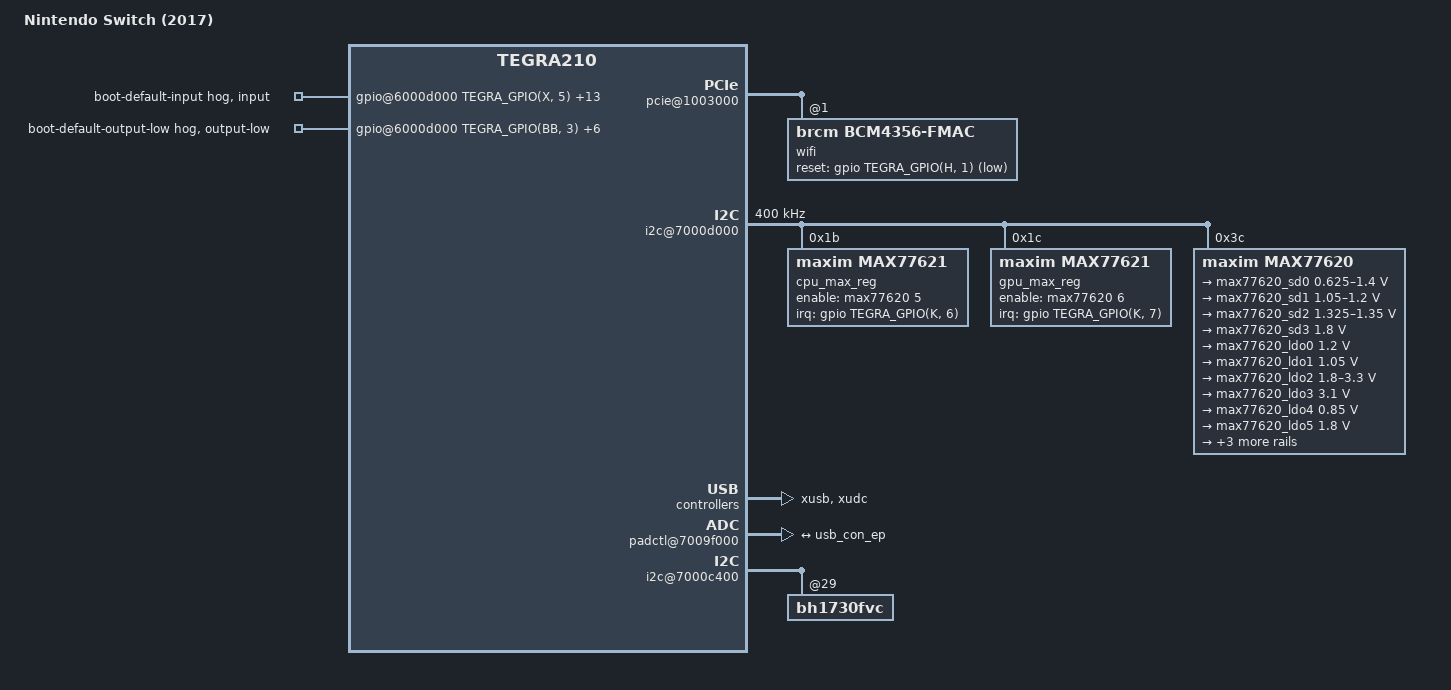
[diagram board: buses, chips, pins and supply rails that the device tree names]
// SPDX-License-Identifier: GPL-2.0
/dts-v1/;

#include "tegra210-nx.dtsi"

/ {
	model = "Nintendo Switch (2017)";
	compatible = "nintendo,icosa", "nvidia,tegra210";
	serial-number = "1234";

	#address-cells = <2>;
	#size-cells = <2>;

	external-memory-controller@7001b000 {
		status = "okay";

		clocks = <&tegra_car TEGRA210_CLK_EMC>,
			<&tegra_car TEGRA210_CLK_PLL_M>,
			<&tegra_car TEGRA210_CLK_PLL_C>,
			<&tegra_car TEGRA210_CLK_PLL_P>,
			<&tegra_car TEGRA210_CLK_CLK_M>,
			<&tegra_car TEGRA210_CLK_PLL_MB>,
			<&tegra_car TEGRA210_CLK_PLL_MB_UD>,
			<&tegra_car TEGRA210_CLK_PLL_P_UD>;

		clock-names = "emc", "pll_m", "pll_c", "pll_p", "mclk",
			"pll_mb", "pll_mb_ud", "pll_p_ud";
		#thermal-sensor-cells = <0>;

		nvidia,use-smc-emc-tables;
	};

	pcie@1003000 {
		status = "okay";

		hvddio-pex-supply = <&max77620_sd3>;
		dvddio-pex-supply = <&max77620_ldo1>;
		vddio-pex-ctl-supply = <&max77620_sd3>;

		pci@1,0 {
			phys = <&{/padctl@7009f000/pads/pcie/lanes/pcie-1}>,
				<&{/padctl@7009f000/pads/pcie/lanes/pcie-2}>,
				<&{/padctl@7009f000/pads/pcie/lanes/pcie-3}>,
				<&{/padctl@7009f000/pads/pcie/lanes/pcie-4}>;
			phy-names = "pcie-0", "pcie-1", "pcie-2", "pcie-3";
			nvidia,num-lanes = <4>;
			status = "okay";
		};

		pci@2,0 {
			phys = <&{/padctl@7009f000/pads/pcie/lanes/pcie-0}>;
			phy-names = "pcie-0";
			status = "okay";

			wifi@1 { /* PCIE-0 (Port 1) */
				status = "okay";
				compatible = "brcm,bcm4356-fmac";
				reg = <1>;
				reset-gpios = <&gpio TEGRA_GPIO(H, 1) GPIO_ACTIVE_LOW>;
			};
		};
	};

	host1x@50000000 {
		dsia: dsi@54300000 {
			avdd-dsi-csi-supply = <&max77620_gpio7>;
		};

		dc@54200000 {
			avdd_dsi_csi-supply = <&max77620_gpio7>;
		};

		sor1: sor@54580000 {
			/* use odin hdmi defaults */
			compatible = "nvidia,tegra210-sor1-odin";
		};

		vi: i2c@546c0000 {
			avdd_dsi_csi-supply = <&max77620_gpio7>;
        };
	};

	gpio@6000d000 {
		boot-default-input {
			gpio-hog;
			input;
			gpios = <
				TEGRA_GPIO(X, 5) GPIO_ACTIVE_HIGH /* Power Button (Not connected) */
				TEGRA_GPIO(Y, 1) GPIO_ACTIVE_LOW /* Home Button (RCM) */
				TEGRA_GPIO(S, 1) GPIO_ACTIVE_LOW /* Charger IC (BQ24193) Battery Charge Status */
				TEGRA_GPIO(S, 3) GPIO_ACTIVE_LOW /* Gamecard Detect */
				TEGRA_GPIO(Z, 3) GPIO_ACTIVE_LOW /* SD Card Write Protected */
				TEGRA_GPIO(H, 2) GPIO_ACTIVE_LOW /* Wi-Fi Wake Host */
				TEGRA_GPIO(H, 5) GPIO_ACTIVE_LOW /* Bluetooth - BT Module -> Wake AP */
				TEGRA_GPIO(K, 0) GPIO_ACTIVE_HIGH /* Bluetooth Gpio2 */
				TEGRA_GPIO(K, 1) GPIO_ACTIVE_HIGH /* Bluetooth Gpio3 */
				TEGRA_GPIO(K, 2) GPIO_ACTIVE_HIGH /* Bluetooth Gpio4 */
				TEGRA_GPIO(V, 3) GPIO_ACTIVE_LOW /* Unused */

				TEGRA_GPIO(P, 0) GPIO_ACTIVE_LOW  /* SDEV Odin/Modin */
				TEGRA_GPIO(BB, 2) GPIO_ACTIVE_HIGH /* Ram Code 3 */
				TEGRA_GPIO(CC, 2) GPIO_ACTIVE_HIGH /* Ram Code 2 */
			>;
			line-name = "boot-default-input";
		};

		boot-default-output-low {
			gpio-hog;
			output-low;
			gpios = <
				TEGRA_GPIO(BB, 3) GPIO_ACTIVE_HIGH /* Gamecard Reset */
				TEGRA_GPIO(V, 5) GPIO_ACTIVE_HIGH  /* USB-PD (BM92T36) Reset. Use it to reset bm92t (128 ms debounce)? */
				TEGRA_GPIO(K, 5) GPIO_ACTIVE_HIGH  /* USB-PD (BM92T36) VCONN Power Enable. HOS sets it to 0 */
				TEGRA_GPIO(J, 5) GPIO_ACTIVE_HIGH  /* Charger IC (BQ24193) Charge Select 1 */
				TEGRA_GPIO(L, 0) GPIO_ACTIVE_HIGH  /* Charger IC (BQ24193) Charge Select 2 */
				TEGRA_GPIO(H, 0) GPIO_ACTIVE_HIGH  /* Wi-Fi RF Disable */
				TEGRA_GPIO(H, 7) GPIO_ACTIVE_HIGH  /* TODO: What's this? Bluetooth Gpio5 */
			>;
			line-name = "boot-default-output-low";
		};
	};

	pinmux: pinmux@700008d4 {
		pinctrl-names = "default", "drive", "unused";
		pinctrl-0 = <&pinmux_default>;
		pinctrl-1 = <&drive_default>;
		pinctrl-2 = <&pinmux_unused_lowpower>;

		pinmux_default: common {
			/* SFIO Pin Configuration */
			aud_mclk_pbb0 { /* 3180 */
				nvidia,pins = "aud_mclk_pbb0";
				nvidia,function = "aud";
				nvidia,pull = <TEGRA_PIN_PULL_DOWN>;
				nvidia,tristate = <TEGRA_PIN_DISABLE>;
				nvidia,enable-input = <TEGRA_PIN_DISABLE>;
			};

			dvfs_pwm_pbb1 { /* 3184 */
				nvidia,pins = "dvfs_pwm_pbb1";
				nvidia,function = "cldvfs";
				nvidia,pull = <TEGRA_PIN_PULL_DOWN>;
				nvidia,tristate = <TEGRA_PIN_ENABLE>;
				nvidia,enable-input = <TEGRA_PIN_DISABLE>;
			};

			dap1_din_pb1 { /* 3128 */
				nvidia,pins = "dap1_din_pb1";
				nvidia,function = "i2s1";
				nvidia,pull = <TEGRA_PIN_PULL_DOWN>;
				nvidia,tristate = <TEGRA_PIN_ENABLE>;
				nvidia,enable-input = <TEGRA_PIN_DISABLE>;
			};

			dap1_dout_pb2 { /* 312c */
				nvidia,pins = "dap1_dout_pb2";
				nvidia,function = "i2s1";
				nvidia,pull = <TEGRA_PIN_PULL_DOWN>;
				nvidia,tristate = <TEGRA_PIN_DISABLE>;
				nvidia,enable-input = <TEGRA_PIN_DISABLE>;
			};

			dap1_fs_pb0 { /* 3124 */
				nvidia,pins = "dap1_fs_pb0";
				nvidia,function = "i2s1";
				nvidia,pull = <TEGRA_PIN_PULL_DOWN>;
				nvidia,tristate = <TEGRA_PIN_DISABLE>;
				nvidia,enable-input = <TEGRA_PIN_DISABLE>;
			};

			dap1_sclk_pb3 { /* 3030 */
				nvidia,pins = "dap1_sclk_pb3";
				nvidia,function = "i2s1";
				nvidia,pull = <TEGRA_PIN_PULL_DOWN>;
				nvidia,tristate = <TEGRA_PIN_DISABLE>;
				nvidia,enable-input = <TEGRA_PIN_DISABLE>;
			};

			dmic1_clk_pe0 { /* 30a4 */
				nvidia,pins = "dmic1_clk_pe0";
				nvidia,function = "dmic1";
				nvidia,pull = <TEGRA_PIN_PULL_DOWN>;
				nvidia,tristate = <TEGRA_PIN_ENABLE>;
				nvidia,enable-input = <TEGRA_PIN_DISABLE>;
			};

			dmic1_dat_pe1 { /* 30a8 */
				nvidia,pins = "dmic1_dat_pe1";
				nvidia,function = "dmic1";
				nvidia,pull = <TEGRA_PIN_PULL_DOWN>;
				nvidia,tristate = <TEGRA_PIN_ENABLE>;
				nvidia,enable-input = <TEGRA_PIN_DISABLE>;
			};

			dmic2_clk_pe2 { /* 30ac */
				nvidia,pins = "dmic2_clk_pe2";
				nvidia,function = "dmic2";
				nvidia,pull = <TEGRA_PIN_PULL_DOWN>;
				nvidia,tristate = <TEGRA_PIN_ENABLE>;
				nvidia,enable-input = <TEGRA_PIN_DISABLE>;
			};

			dmic2_dat_pe3 { /* 30b0 */
				nvidia,pins = "dmic2_dat_pe3";
				nvidia,function = "dmic2";
				nvidia,pull = <TEGRA_PIN_PULL_DOWN>;
				nvidia,tristate = <TEGRA_PIN_ENABLE>;
				nvidia,enable-input = <TEGRA_PIN_DISABLE>;
			};

			/* SD Card Power Enable */
			dmic3_clk_pe4 { /* 30b4 */
				nvidia,pins = "dmic3_clk_pe4";
				nvidia,function = "rsvd3";
				nvidia,pull = <TEGRA_PIN_PULL_DOWN>;
				nvidia,tristate = <TEGRA_PIN_DISABLE>;
				nvidia,enable-input = <TEGRA_PIN_DISABLE>;
			};

			/* Gamecard Power Enable */
			dmic3_dat_pe5 { /* 30b8 */
				nvidia,pins = "dmic3_dat_pe5";
				nvidia,function = "rsvd3";
				nvidia,pull = <TEGRA_PIN_PULL_DOWN>;
				nvidia,tristate = <TEGRA_PIN_DISABLE>;
				nvidia,enable-input = <TEGRA_PIN_DISABLE>;
			};

			gen3_i2c_scl_pf0 { /* 30cc */
				nvidia,pins = "gen3_i2c_scl_pf0";
				nvidia,function = "i2c3";
				nvidia,pull = <TEGRA_PIN_PULL_NONE>;
				nvidia,tristate = <TEGRA_PIN_DISABLE>;
				nvidia,enable-input = <TEGRA_PIN_ENABLE>;
				nvidia,io-high-voltage = <TEGRA_PIN_DISABLE>;
			};

			gen3_i2c_sda_pf1 { /* 30d0 */
				nvidia,pins = "gen3_i2c_sda_pf1";
				nvidia,function = "i2c3";
				nvidia,pull = <TEGRA_PIN_PULL_NONE>;
				nvidia,tristate = <TEGRA_PIN_DISABLE>;
				nvidia,enable-input = <TEGRA_PIN_ENABLE>;
				nvidia,io-high-voltage = <TEGRA_PIN_DISABLE>;
			};

			cam_i2c_scl_ps2 { /* 30d4 */
				nvidia,pins = "cam_i2c_scl_ps2";
				nvidia,function = "i2cvi";
				nvidia,pull = <TEGRA_PIN_PULL_DOWN>;
				nvidia,tristate = <TEGRA_PIN_ENABLE>;
				nvidia,enable-input = <TEGRA_PIN_DISABLE>;
				nvidia,io-high-voltage = <TEGRA_PIN_ENABLE>;
			};

			/* Gamecard Detect */
			cam_i2c_sda_ps3 { /* 30d8 */
				nvidia,pins = "cam_i2c_sda_ps3";
				nvidia,function = "rsvd2";
				nvidia,pull = <TEGRA_PIN_PULL_UP>;
				nvidia,tristate = <TEGRA_PIN_ENABLE>;
				nvidia,enable-input = <TEGRA_PIN_ENABLE>;
				nvidia,io-high-voltage = <TEGRA_PIN_DISABLE>;
			};

			cam1_mclk_ps0 { /* 3154 */
				nvidia,pins = "cam1_mclk_ps0";
				nvidia,function = "rsvd1";
				nvidia,pull = <TEGRA_PIN_PULL_DOWN>;
				nvidia,tristate = <TEGRA_PIN_ENABLE>;
				nvidia,enable-input = <TEGRA_PIN_ENABLE>;
			};

			/* Charger IC (BQ24193) Battery Charge Status */
			cam2_mclk_ps1 { /* 3158 */
				nvidia,pins = "cam2_mclk_ps1";
				nvidia,function = "rsvd1";
				nvidia,pull = <TEGRA_PIN_PULL_NONE>;
				nvidia,tristate = <TEGRA_PIN_ENABLE>;
				nvidia,enable-input = <TEGRA_PIN_ENABLE>;
			};

			pex_l0_clkreq_n_pa1 { /* 303c PARKED */
				nvidia,pins = "pex_l0_clkreq_n_pa1";
				nvidia,function = "pe0";
				nvidia,pull = <TEGRA_PIN_PULL_NONE>;
				nvidia,tristate = <TEGRA_PIN_ENABLE>;
				nvidia,enable-input = <TEGRA_PIN_DISABLE>;
				nvidia,io-high-voltage = <TEGRA_PIN_DISABLE>;
			};

			pex_l0_rst_n_pa0 { /* 3038 */
				nvidia,pins = "pex_l0_rst_n_pa0";
				nvidia,function = "pe0";
				nvidia,pull = <TEGRA_PIN_PULL_NONE>;
				nvidia,tristate = <TEGRA_PIN_DISABLE>;
				nvidia,enable-input = <TEGRA_PIN_DISABLE>;
				nvidia,io-high-voltage = <TEGRA_PIN_DISABLE>;
			};

			pex_l1_clkreq_n_pa4 { /* 3048 */
				nvidia,pins = "pex_l1_clkreq_n_pa4";
				nvidia,function = "pe1";
				nvidia,pull = <TEGRA_PIN_PULL_NONE>;
				nvidia,tristate = <TEGRA_PIN_DISABLE>;
				nvidia,enable-input = <TEGRA_PIN_ENABLE>;
				nvidia,io-high-voltage = <TEGRA_PIN_DISABLE>;
			};

			pex_l1_rst_n_pa3 { /* 3044 */
				nvidia,pins = "pex_l1_rst_n_pa3";
				nvidia,function = "pe1";
				nvidia,pull = <TEGRA_PIN_PULL_NONE>;
				nvidia,tristate = <TEGRA_PIN_DISABLE>;
				nvidia,enable-input = <TEGRA_PIN_DISABLE>;
				nvidia,io-high-voltage = <TEGRA_PIN_DISABLE>;
			};

			pex_wake_n_pa2 { /* 3040 */
				nvidia,pins = "pex_wake_n_pa2";
				nvidia,function = "pe";
				nvidia,pull = <TEGRA_PIN_PULL_NONE>;
				nvidia,tristate = <TEGRA_PIN_ENABLE>;
				nvidia,enable-input = <TEGRA_PIN_ENABLE>;
				nvidia,io-high-voltage = <TEGRA_PIN_DISABLE>;
			};

			sdmmc1_clk_pm0 {  /* 3000 */
				nvidia,pins = "sdmmc1_clk_pm0";
				nvidia,function = "sdmmc1";
				nvidia,pull = <TEGRA_PIN_PULL_DOWN>;
				nvidia,tristate = <TEGRA_PIN_DISABLE>;
				nvidia,enable-input = <TEGRA_PIN_ENABLE>;
			};

			sdmmc1_cmd_pm1 { /* 3004 */
				nvidia,pins = "sdmmc1_cmd_pm1";
				nvidia,function = "sdmmc1";
				nvidia,pull = <TEGRA_PIN_PULL_UP>;
				nvidia,tristate = <TEGRA_PIN_DISABLE>;
				nvidia,enable-input = <TEGRA_PIN_ENABLE>;
			};

			sdmmc1_dat0_pm5 { /* 3008 */
				nvidia,pins = "sdmmc1_dat0_pm5";
				nvidia,function = "sdmmc1";
				nvidia,pull = <TEGRA_PIN_PULL_UP>;
				nvidia,tristate = <TEGRA_PIN_DISABLE>;
				nvidia,enable-input = <TEGRA_PIN_ENABLE>;
			};

			sdmmc1_dat1_pm4 { /* 300C */
				nvidia,pins = "sdmmc1_dat1_pm4";
				nvidia,function = "sdmmc1";
				nvidia,pull = <TEGRA_PIN_PULL_UP>;
				nvidia,tristate = <TEGRA_PIN_DISABLE>;
				nvidia,enable-input = <TEGRA_PIN_ENABLE>;
			};

			sdmmc1_dat2_pm3 { /* 3010 */
				nvidia,pins = "sdmmc1_dat2_pm3";
				nvidia,function = "sdmmc1";
				nvidia,pull = <TEGRA_PIN_PULL_UP>;
				nvidia,tristate = <TEGRA_PIN_DISABLE>;
				nvidia,enable-input = <TEGRA_PIN_ENABLE>;
			};

			sdmmc1_dat3_pm2 { /* 3014 */
				nvidia,pins = "sdmmc1_dat3_pm2";
				nvidia,function = "sdmmc1";
				nvidia,pull = <TEGRA_PIN_PULL_UP>;
				nvidia,tristate = <TEGRA_PIN_DISABLE>;
				nvidia,enable-input = <TEGRA_PIN_ENABLE>;
			};

			sdmmc3_clk_pp0 { /* 301c */
				nvidia,pins = "sdmmc3_clk_pp0";
				nvidia,function = "rsvd1";
				nvidia,pull = <TEGRA_PIN_PULL_DOWN>;
				nvidia,tristate = <TEGRA_PIN_ENABLE>;
				nvidia,enable-input = <TEGRA_PIN_ENABLE>;
			};

			sdmmc3_cmd_pp1 { /* 3020 */
				nvidia,pins = "sdmmc3_cmd_pp1";
				nvidia,function = "rsvd1";
				nvidia,pull = <TEGRA_PIN_PULL_DOWN>;
				nvidia,tristate = <TEGRA_PIN_ENABLE>;
				nvidia,enable-input = <TEGRA_PIN_DISABLE>;
			};

			sdmmc3_dat0_pp5 { /* 3024 */
				nvidia,pins = "sdmmc3_dat0_pp5";
				nvidia,function = "rsvd1";
				nvidia,pull = <TEGRA_PIN_PULL_NONE>;
				nvidia,tristate = <TEGRA_PIN_ENABLE>;
				nvidia,enable-input = <TEGRA_PIN_ENABLE>;
			};

			sdmmc3_dat1_pp4 { /* 3028 */
				nvidia,pins = "sdmmc3_dat1_pp4";
				nvidia,function = "rsvd1";
				nvidia,pull = <TEGRA_PIN_PULL_NONE>;
				nvidia,tristate = <TEGRA_PIN_ENABLE>;
				nvidia,enable-input = <TEGRA_PIN_ENABLE>;
			};

			sdmmc3_dat2_pp3 { /* 302C */
				nvidia,pins = "sdmmc3_dat2_pp3";
				nvidia,function = "rsvd1";
				nvidia,pull = <TEGRA_PIN_PULL_NONE>;
				nvidia,tristate = <TEGRA_PIN_ENABLE>;
				nvidia,enable-input = <TEGRA_PIN_ENABLE>;
			};

			sdmmc3_dat3_pp2 { /* 3030 */
				nvidia,pins = "sdmmc3_dat3_pp2";
				nvidia,function = "rsvd1";
				nvidia,pull = <TEGRA_PIN_PULL_NONE>;
				nvidia,tristate = <TEGRA_PIN_ENABLE>;
				nvidia,enable-input = <TEGRA_PIN_ENABLE>;
			};

			shutdown { /* 3178 */
				nvidia,pins = "shutdown";
				nvidia,function = "shutdown";
				nvidia,pull = <TEGRA_PIN_PULL_NONE>;
				nvidia,tristate = <TEGRA_PIN_DISABLE>;
				nvidia,enable-input = <TEGRA_PIN_DISABLE>;
			};

			lcd_te_py2 { /* 31f8 */
				nvidia,pins = "lcd_te_py2";
				nvidia,function = "displaya";
				nvidia,pull = <TEGRA_PIN_PULL_DOWN>;
				nvidia,tristate = <TEGRA_PIN_ENABLE>;
				nvidia,enable-input = <TEGRA_PIN_DISABLE>;
			};

			/* LCD Backlight PWM */
			lcd_bl_pwm_pv0 { /* 31fc */
				nvidia,pins = "lcd_bl_pwm_pv0";
				nvidia,function = "pwm0";
				nvidia,pull = <TEGRA_PIN_PULL_DOWN>;
				nvidia,tristate = <TEGRA_PIN_DISABLE>;
				nvidia,enable-input = <TEGRA_PIN_DISABLE>;
			};

			pwr_i2c_scl_py3 { /* 30dc */
				nvidia,pins = "pwr_i2c_scl_py3";
				nvidia,function = "i2cpmu";
				nvidia,pull = <TEGRA_PIN_PULL_NONE>;
				nvidia,tristate = <TEGRA_PIN_DISABLE>;
				nvidia,enable-input = <TEGRA_PIN_ENABLE>;
				nvidia,io-high-voltage = <TEGRA_PIN_DISABLE>;
			};

			pwr_i2c_sda_py4 { /* 30e0 */
				nvidia,pins = "pwr_i2c_sda_py4";
				nvidia,function = "i2cpmu";
				nvidia,pull = <TEGRA_PIN_PULL_NONE>;
				nvidia,tristate = <TEGRA_PIN_DISABLE>;
				nvidia,enable-input = <TEGRA_PIN_ENABLE>;
				nvidia,io-high-voltage = <TEGRA_PIN_DISABLE>;
			};

			clk_32k_in { /* 3160 */
				nvidia,pins = "clk_32k_in";
				nvidia,function = "clk";
				nvidia,pull = <TEGRA_PIN_PULL_NONE>;
				nvidia,tristate = <TEGRA_PIN_DISABLE>;
				nvidia,enable-input = <TEGRA_PIN_DISABLE>;
			};

			clk_32k_out_py5 { /* 3164 */
				nvidia,pins = "clk_32k_out_py5";
				nvidia,function = "soc";
				nvidia,pull = <TEGRA_PIN_PULL_NONE>;
				nvidia,tristate = <TEGRA_PIN_ENABLE>;
				nvidia,enable-input = <TEGRA_PIN_ENABLE>;
			};

			/* SD Card Detect */
			pz1 {
				nvidia,pins = "pz1";
				nvidia,function = "rsvd2";
				nvidia,pull = <TEGRA_PIN_PULL_UP>;
				nvidia,tristate = <TEGRA_PIN_DISABLE>;
				nvidia,enable-input = <TEGRA_PIN_ENABLE>;
			};

			/* Audio Codec (ALC5639) Power Enable */
			pz4 { /* 328c */
				nvidia,pins = "pz4";
				nvidia,function = "rsvd1";
				nvidia,pull = <TEGRA_PIN_PULL_DOWN>;
				nvidia,tristate = <TEGRA_PIN_DISABLE>;
				nvidia,enable-input = <TEGRA_PIN_DISABLE>;
			};

			pz5 { /*3290 */
				nvidia,pins = "pz5";
				nvidia,function = "soc";
				nvidia,pull = <TEGRA_PIN_PULL_UP>;
				nvidia,tristate = <TEGRA_PIN_ENABLE>;
				nvidia,enable-input = <TEGRA_PIN_ENABLE>;
			};

			clk_req { /* 316c */
				nvidia,pins = "clk_req";
				nvidia,function = "sys";
				nvidia,pull = <TEGRA_PIN_PULL_NONE>;
				nvidia,tristate = <TEGRA_PIN_DISABLE>;
				nvidia,enable-input = <TEGRA_PIN_ENABLE>;
			};

			core_pwr_req { /* 317c */
				nvidia,pins = "core_pwr_req";
				nvidia,function = "core";
				nvidia,pull = <TEGRA_PIN_PULL_NONE>;
				nvidia,tristate = <TEGRA_PIN_DISABLE>;
				nvidia,enable-input = <TEGRA_PIN_DISABLE>;
			};

			/* 3170 */
			cpu_pwr_req {
				nvidia,pins = "cpu_pwr_req";
				nvidia,function = "cpu";
				nvidia,pull = <TEGRA_PIN_PULL_NONE>;
				nvidia,tristate = <TEGRA_PIN_DISABLE>;
				nvidia,enable-input = <TEGRA_PIN_DISABLE>;
			};

			pwr_int_n { /* 3174 */
				nvidia,pins = "pwr_int_n";
				nvidia,function = "pmi";
				nvidia,pull = <TEGRA_PIN_PULL_UP>;
				nvidia,tristate = <TEGRA_PIN_DISABLE>;
				nvidia,enable-input = <TEGRA_PIN_ENABLE>;
			};

			dap4_din_pj5 { /* 3148 */
				nvidia,pins = "dap4_din_pj5";
				nvidia,function = "rsvd1";
				nvidia,pull = <TEGRA_PIN_PULL_DOWN>;
				nvidia,tristate = <TEGRA_PIN_DISABLE>;
				nvidia,enable-input = <TEGRA_PIN_DISABLE>;
			};

			dap4_dout_pj6 { /* 314c */
				nvidia,pins = "dap4_dout_pj6";
				nvidia,function = "rsvd1";
				nvidia,pull = <TEGRA_PIN_PULL_DOWN>;
				nvidia,tristate = <TEGRA_PIN_ENABLE>;
				nvidia,enable-input = <TEGRA_PIN_DISABLE>;
			};

			dap4_fs_pj4 { /* 3144 */
				nvidia,pins = "dap4_fs_pj4";
				nvidia,function = "rsvd1";
				nvidia,pull = <TEGRA_PIN_PULL_DOWN>;
				nvidia,tristate = <TEGRA_PIN_ENABLE>;
				nvidia,enable-input = <TEGRA_PIN_DISABLE>;
			};

			/* Touchscreen (4CD60D) Reset */
			dap4_sclk_pj7 { /* 3150 */
				nvidia,pins = "dap4_sclk_pj7";
				nvidia,function = "rsvd1";
				nvidia,pull = <TEGRA_PIN_PULL_DOWN>;
				nvidia,tristate = <TEGRA_PIN_DISABLE>;
				nvidia,enable-input = <TEGRA_PIN_DISABLE>;
			};

			gen1_i2c_scl_pj1 { /* 30bc */
				nvidia,pins = "gen1_i2c_scl_pj1";
				nvidia,function = "i2c1";
				nvidia,pull = <TEGRA_PIN_PULL_NONE>;
				nvidia,tristate = <TEGRA_PIN_DISABLE>;
				nvidia,enable-input = <TEGRA_PIN_ENABLE>;
				nvidia,io-high-voltage = <TEGRA_PIN_DISABLE>;
			};

			gen1_i2c_sda_pj0 { /* 30c0 */
				nvidia,pins = "gen1_i2c_sda_pj0";
				nvidia,function = "i2c1";
				nvidia,pull = <TEGRA_PIN_PULL_NONE>;
				nvidia,tristate = <TEGRA_PIN_DISABLE>;
				nvidia,enable-input = <TEGRA_PIN_ENABLE>;
				nvidia,io-high-voltage = <TEGRA_PIN_DISABLE>;
			};

			gen2_i2c_scl_pj2 { /* 30c4 */
				nvidia,pins = "gen2_i2c_scl_pj2";
				nvidia,function = "i2c2";
				nvidia,pull = <TEGRA_PIN_PULL_NONE>;
				nvidia,tristate = <TEGRA_PIN_DISABLE>;
				nvidia,enable-input = <TEGRA_PIN_ENABLE>;
				nvidia,io-high-voltage = <TEGRA_PIN_DISABLE>;
			};

			gen2_i2c_sda_pj3 { /* 30c8 */
				nvidia,pins = "gen2_i2c_sda_pj3";
				nvidia,function = "i2c2";
				nvidia,pull = <TEGRA_PIN_PULL_NONE>;
				nvidia,tristate = <TEGRA_PIN_DISABLE>;
				nvidia,enable-input = <TEGRA_PIN_ENABLE>;
				nvidia,io-high-voltage = <TEGRA_PIN_DISABLE>;
			};

			uart1_tx_pu0 { /* 30e4 */
				nvidia,pins = "uart1_tx_pu0";
				nvidia,function = "uarta";
				nvidia,pull = <TEGRA_PIN_PULL_NONE>;
				nvidia,tristate = <TEGRA_PIN_DISABLE>;
				nvidia,enable-input = <TEGRA_PIN_DISABLE>;
			};

			uart1_rx_pu1 { /* 30e8 */
				nvidia,pins = "uart1_rx_pu1";
				nvidia,function = "uarta";
				nvidia,pull = <TEGRA_PIN_PULL_UP>;
				nvidia,tristate = <TEGRA_PIN_ENABLE>;
				nvidia,enable-input = <TEGRA_PIN_ENABLE>;
			};

			uart1_rts_pu2 { /* 30ec */
				nvidia,pins = "uart1_rts_pu2";
				nvidia,function = "uarta";
				nvidia,pull = <TEGRA_PIN_PULL_NONE>;
				nvidia,tristate = <TEGRA_PIN_DISABLE>;
				nvidia,enable-input = <TEGRA_PIN_DISABLE>;
			};

			uart1_cts_pu3 { /* 30f0 */
				nvidia,pins = "uart1_cts_pu3";
				nvidia,function = "uarta";
				nvidia,pull = <TEGRA_PIN_PULL_DOWN>;
				nvidia,tristate = <TEGRA_PIN_ENABLE>;
				nvidia,enable-input = <TEGRA_PIN_ENABLE>;
			};

			jtag_rtck { /* 315c */
				nvidia,pins = "jtag_rtck";
				nvidia,function = "jtag";
				nvidia,pull = <TEGRA_PIN_PULL_UP>;
				nvidia,tristate = <TEGRA_PIN_DISABLE>;
				nvidia,enable-input = <TEGRA_PIN_DISABLE>;
			};

			/* Bluetooth GPIO2 */
			pk0 { /* 3254 */
				nvidia,pins = "pk0";
				nvidia,function = "rsvd2";
				nvidia,pull = <TEGRA_PIN_PULL_DOWN>;
				nvidia,tristate = <TEGRA_PIN_DISABLE>;
				nvidia,enable-input = <TEGRA_PIN_ENABLE>;
			};

			/* Bluetooth GPIO3 */
			pk1 { /* 3258 */
				nvidia,pins = "pk1";
				nvidia,function = "rsvd2";
				nvidia,pull = <TEGRA_PIN_PULL_DOWN>;
				nvidia,tristate = <TEGRA_PIN_DISABLE>;
				nvidia,enable-input = <TEGRA_PIN_ENABLE>;
			};

			/* Bluetooth GPIO4 */
			pk2 { /* 325c */
				nvidia,pins = "pk2";
				nvidia,function = "rsvd2";
				nvidia,pull = <TEGRA_PIN_PULL_NONE>;
				nvidia,tristate = <TEGRA_PIN_DISABLE>;
				nvidia,enable-input = <TEGRA_PIN_ENABLE>;
			};

			/* Joycon (R) Charge Enable */
			pk3 { /* 3260 */
				nvidia,pins = "pk3";
				nvidia,function = "rsvd2";
				nvidia,pull = <TEGRA_PIN_PULL_DOWN>;
				nvidia,tristate = <TEGRA_PIN_DISABLE>;
				nvidia,enable-input = <TEGRA_PIN_DISABLE>;
			};

			/* Joycon (L) Charge Enable */
			spdif_in_pcc3 { /* 31a4 */
				nvidia,pins = "spdif_in_pcc3";
				nvidia,function = "rsvd1";
				nvidia,pull = <TEGRA_PIN_PULL_DOWN>;
				nvidia,tristate = <TEGRA_PIN_DISABLE>;
				nvidia,enable-input = <TEGRA_PIN_DISABLE>;
			};

			pl1 { /* 3278 */
				nvidia,pins = "pl1";
				nvidia,function = "soc";
				nvidia,pull = <TEGRA_PIN_PULL_UP>;
				nvidia,tristate = <TEGRA_PIN_ENABLE>;
				nvidia,enable-input = <TEGRA_PIN_ENABLE>;
			};

			spi1_mosi_pc0 { /* 3050 */
				nvidia,pins = "spi1_mosi_pc0";
				nvidia,function = "rsvd1";
				nvidia,pull = <TEGRA_PIN_PULL_DOWN>;
				nvidia,tristate = <TEGRA_PIN_ENABLE>;
				nvidia,enable-input = <TEGRA_PIN_DISABLE>;
			};

			spi1_miso_pc1 { /* 3054 */
				nvidia,pins = "spi1_miso_pc1";
				nvidia,function = "rsvd1";
				nvidia,pull = <TEGRA_PIN_PULL_DOWN>;
				nvidia,tristate = <TEGRA_PIN_ENABLE>;
				nvidia,enable-input = <TEGRA_PIN_DISABLE>;
			};

			spi1_sck_pc2 { /* 3058 */
				nvidia,pins = "spi1_sck_pc2";
				nvidia,function = "rsvd1";
				nvidia,pull = <TEGRA_PIN_PULL_DOWN>;
				nvidia,tristate = <TEGRA_PIN_ENABLE>;
				nvidia,enable-input = <TEGRA_PIN_DISABLE>;
			};

			spi1_cs0_pc3 { /* 305c */
				nvidia,pins = "spi1_cs0_pc3";
				nvidia,function = "rsvd1";
				nvidia,pull = <TEGRA_PIN_PULL_DOWN>;
				nvidia,tristate = <TEGRA_PIN_ENABLE>;
				nvidia,enable-input = <TEGRA_PIN_DISABLE>;
			};

			spi1_cs1_pc4 { /* 3060 */
				nvidia,pins = "spi1_cs1_pc4";
				nvidia,function = "rsvd1";
				nvidia,pull = <TEGRA_PIN_PULL_DOWN>;
				nvidia,tristate = <TEGRA_PIN_ENABLE>;
				nvidia,enable-input = <TEGRA_PIN_DISABLE>;
			};

			/* IMU access */
			spi4_mosi_pc7 {
				nvidia,pins = "spi4_mosi_pc7";
				nvidia,function = "spi4";
				nvidia,pull = <TEGRA_PIN_PULL_DOWN>;
				nvidia,tristate = <TEGRA_PIN_DISABLE>;
				nvidia,enable-input = <TEGRA_PIN_DISABLE>;
			};

			spi4_miso_pd0 { /* 307c */
				nvidia,pins = "spi4_miso_pd0";
				nvidia,function = "spi4";
				nvidia,pull = <TEGRA_PIN_PULL_UP>;
				nvidia,tristate = <TEGRA_PIN_ENABLE>;
				nvidia,enable-input = <TEGRA_PIN_ENABLE>;
			};

			spi4_sck_pc5 { /* 3080 */
				nvidia,pins = "spi4_sck_pc5";
				nvidia,function = "spi4";
				nvidia,pull = <TEGRA_PIN_PULL_DOWN>;
				nvidia,tristate = <TEGRA_PIN_DISABLE>;
				nvidia,enable-input = <TEGRA_PIN_DISABLE>;
			};

			spi4_cs0_pc6 { /* 3084 */
				nvidia,pins = "spi4_cs0_pc6";
				nvidia,function = "spi4";
				nvidia,pull = <TEGRA_PIN_PULL_UP>;
				nvidia,tristate = <TEGRA_PIN_DISABLE>;
				nvidia,enable-input = <TEGRA_PIN_DISABLE>;
			};

			uart2_tx_pg0 { /* 30f4 */
				nvidia,pins = "uart2_tx_pg0";
				nvidia,function = "uartb";
				nvidia,pull = <TEGRA_PIN_PULL_NONE>;
				nvidia,tristate = <TEGRA_PIN_DISABLE>;
				nvidia,enable-input = <TEGRA_PIN_DISABLE>;
			};

			uart2_rx_pg1 { /* 30f8 */
				nvidia,pins = "uart2_rx_pg1";
				nvidia,function = "uartb";
				nvidia,pull = <TEGRA_PIN_PULL_NONE>;
				nvidia,tristate = <TEGRA_PIN_DISABLE>;
				nvidia,enable-input = <TEGRA_PIN_ENABLE>;
			};

			uart2_rts_pg2 { /* 30fc */
				nvidia,pins = "uart2_rts_pg2";
				nvidia,function = "uartb";
				nvidia,pull = <TEGRA_PIN_PULL_NONE>;
				nvidia,tristate = <TEGRA_PIN_DISABLE>;
				nvidia,enable-input = <TEGRA_PIN_DISABLE>;
			};

			uart2_cts_pg3 { /* 3100 */
				nvidia,pins = "uart2_cts_pg3";
				nvidia,function = "uartb";
				nvidia,pull = <TEGRA_PIN_PULL_NONE>;
				nvidia,tristate = <TEGRA_PIN_ENABLE>;
				nvidia,enable-input = <TEGRA_PIN_ENABLE>;
			};

			uart3_tx_pd1 { /* 3104 */
				nvidia,pins = "uart3_tx_pd1";
				nvidia,function = "uartc";
				nvidia,pull = <TEGRA_PIN_PULL_NONE>;
				nvidia,tristate = <TEGRA_PIN_DISABLE>;
				nvidia,enable-input = <TEGRA_PIN_DISABLE>;
			};

			uart3_rx_pd2 { /* 3108 */
				nvidia,pins = "uart3_rx_pd2";
				nvidia,function = "uartc";
				nvidia,pull = <TEGRA_PIN_PULL_NONE>;
				nvidia,tristate = <TEGRA_PIN_ENABLE>;
				nvidia,enable-input = <TEGRA_PIN_ENABLE>;
			};

			uart3_rts_pd3 { /* 310C */
				nvidia,pins = "uart3_rts_pd3";
				nvidia,function = "uartc";
				nvidia,pull = <TEGRA_PIN_PULL_DOWN>;
				nvidia,tristate = <TEGRA_PIN_DISABLE>;
				nvidia,enable-input = <TEGRA_PIN_DISABLE>;
			};

			uart3_cts_pd4 { /* 3110 */
				nvidia,pins = "uart3_cts_pd4";
				nvidia,function = "uartc";
				nvidia,pull = <TEGRA_PIN_PULL_NONE>;
				nvidia,tristate = <TEGRA_PIN_ENABLE>;
				nvidia,enable-input = <TEGRA_PIN_ENABLE>;
			};

			uart4_tx_pi4 { /* 3114 */
				nvidia,pins = "uart4_tx_pi4";
				nvidia,function = "uartd";
				nvidia,pull = <TEGRA_PIN_PULL_DOWN>;
				nvidia,tristate = <TEGRA_PIN_DISABLE>;
				nvidia,enable-input = <TEGRA_PIN_DISABLE>;
			};

			uart4_rx_pi5 { /* 3118 */
				nvidia,pins = "uart4_rx_pi5";
				nvidia,function = "uartd";
				nvidia,pull = <TEGRA_PIN_PULL_DOWN>;
				nvidia,tristate = <TEGRA_PIN_ENABLE>;
				nvidia,enable-input = <TEGRA_PIN_ENABLE>;
			};

			uart4_rts_pi6 { /* 311c */
				nvidia,pins = "uart4_rts_pi6";
				nvidia,function = "uartd";
				nvidia,pull = <TEGRA_PIN_PULL_DOWN>;
				nvidia,tristate = <TEGRA_PIN_DISABLE>;
				nvidia,enable-input = <TEGRA_PIN_DISABLE>;
			};

			uart4_cts_pi7 { /* 3120 */
				nvidia,pins = "uart4_cts_pi7";
				nvidia,function = "uartd";
				nvidia,pull = <TEGRA_PIN_PULL_DOWN>;
				nvidia,tristate = <TEGRA_PIN_ENABLE>;
				nvidia,enable-input = <TEGRA_PIN_ENABLE>;
			};

			dap2_din_paa2 { /* 3138 */
				nvidia,pins = "dap2_din_paa2";
				nvidia,function = "i2s2";
				nvidia,pull = <TEGRA_PIN_PULL_DOWN>;
				nvidia,tristate = <TEGRA_PIN_ENABLE>;
				nvidia,enable-input = <TEGRA_PIN_ENABLE>;
			};

			dap2_dout_paa3 { /* 313c */
				nvidia,pins = "dap2_dout_paa3";
				nvidia,function = "i2s2";
				nvidia,pull = <TEGRA_PIN_PULL_DOWN>;
				nvidia,tristate = <TEGRA_PIN_DISABLE>;
				nvidia,enable-input = <TEGRA_PIN_DISABLE>;
			};

			dap2_fs_paa0 { /* 3134 */
				nvidia,pins = "dap2_fs_paa0";
				nvidia,function = "i2s2";
				nvidia,pull = <TEGRA_PIN_PULL_DOWN>;
				nvidia,tristate = <TEGRA_PIN_DISABLE>;
				nvidia,enable-input = <TEGRA_PIN_DISABLE>;
			};

			dap2_sclk_paa1 { /* 3140 */
				nvidia,pins = "dap2_sclk_paa1";
				nvidia,function = "i2s2";
				nvidia,pull = <TEGRA_PIN_PULL_DOWN>;
				nvidia,tristate = <TEGRA_PIN_DISABLE>;
				nvidia,enable-input = <TEGRA_PIN_DISABLE>;
			};

			/* 5V Regulator - USB */
			usb_vbus_en0_pcc4 {
				nvidia,pins = "usb_vbus_en0_pcc4";
				nvidia,function = "rsvd1";
				nvidia,pull = <TEGRA_PIN_PULL_NONE>;
				nvidia,tristate = <TEGRA_PIN_DISABLE>;
				nvidia,enable-input = <TEGRA_PIN_DISABLE>;
				nvidia,io-high-voltage = <TEGRA_PIN_DISABLE>;
			};

			usb_vbus_en1_pcc5 { /* 31ac */
				nvidia,pins = "usb_vbus_en1_pcc5";
				nvidia,function = "rsvd1";
				nvidia,pull = <TEGRA_PIN_PULL_DOWN>;
				nvidia,tristate = <TEGRA_PIN_ENABLE>;
				nvidia,enable-input = <TEGRA_PIN_DISABLE>;
				nvidia,io-high-voltage = <TEGRA_PIN_ENABLE>;
			};

			hdmi_cec_pcc0 { /* 3198 */
				nvidia,pins = "hdmi_cec_pcc0";
				nvidia,function = "rsvd1";
				nvidia,pull = <TEGRA_PIN_PULL_DOWN>;
				nvidia,tristate = <TEGRA_PIN_ENABLE>;
				nvidia,enable-input = <TEGRA_PIN_DISABLE>;
				nvidia,io-high-voltage = <TEGRA_PIN_ENABLE>;
			};

			/* GPIO Pin Configuration */
			dvfs_clk_pbb2 { /* 3188 */
				nvidia,pins = "dvfs_clk_pbb2";
				nvidia,function = "rsvd0";
				nvidia,pull = <TEGRA_PIN_PULL_UP>;
				nvidia,tristate = <TEGRA_PIN_ENABLE>;
				nvidia,enable-input = <TEGRA_PIN_ENABLE>;
			};

			/* Gamecard Reset */
			gpio_x1_aud_pbb3 { /* 318c */
				nvidia,pins = "gpio_x1_aud_pbb3";
				nvidia,function = "rsvd0";
				nvidia,pull = <TEGRA_PIN_PULL_DOWN>;
				nvidia,tristate = <TEGRA_PIN_DISABLE>;
				nvidia,enable-input = <TEGRA_PIN_DISABLE>;
			};

			/* Audio Codec (ALC5639) Alert */
			gpio_x3_aud_pbb4 { /* 3190 */
				nvidia,pins = "gpio_x3_aud_pbb4";
				nvidia,function = "rsvd0";
				nvidia,pull = <TEGRA_PIN_PULL_DOWN>;
				nvidia,tristate = <TEGRA_PIN_ENABLE>;
				nvidia,enable-input = <TEGRA_PIN_ENABLE>;
			};

			/* Joycon (L) Wake Detect */
			pe6 {
				nvidia,pins = "pe6";
				nvidia,function = "rsvd0";
				nvidia,pull = <TEGRA_PIN_PULL_NONE>;
				nvidia,tristate = <TEGRA_PIN_ENABLE>;
				nvidia,enable-input = <TEGRA_PIN_ENABLE>;
			};

			cam_rst_ps4 { /* 31e0 */
				nvidia,pins = "cam_rst_ps4";
				nvidia,function = "rsvd1";
				nvidia,pull = <TEGRA_PIN_PULL_DOWN>;
				nvidia,tristate = <TEGRA_PIN_ENABLE>;
				nvidia,enable-input = <TEGRA_PIN_DISABLE>;
			};

			cam_af_en_ps5 { /* 31e4 */
				nvidia,pins = "cam_af_en_ps5";
				nvidia,function = "rsvd2";
				nvidia,pull = <TEGRA_PIN_PULL_DOWN>;
				nvidia,tristate = <TEGRA_PIN_ENABLE>;
				nvidia,enable-input = <TEGRA_PIN_DISABLE>;
			};

			/* Charger IC (BQ24193) Battery Charge Enable */
			cam_flash_en_ps6 { /* 31e8 */
				nvidia,pins = "cam_flash_en_ps6";
				nvidia,function = "rsvd2";
				nvidia,pull = <TEGRA_PIN_PULL_DOWN>;
				nvidia,tristate = <TEGRA_PIN_DISABLE>;
				nvidia,enable-input = <TEGRA_PIN_DISABLE>;
			};

			/* Fan Tachometer */
			cam1_pwdn_ps7 { /* 31ec */
				nvidia,pins = "cam1_pwdn_ps7";
				nvidia,function = "rsvd1";
				nvidia,pull = <TEGRA_PIN_PULL_UP>;
				nvidia,tristate = <TEGRA_PIN_ENABLE>;
				nvidia,enable-input = <TEGRA_PIN_ENABLE>;
			};

			cam2_pwdn_pt0 { /* 31f0 */
				nvidia,pins = "cam2_pwdn_pt0";
				nvidia,function = "rsvd1";
				nvidia,pull = <TEGRA_PIN_PULL_DOWN>;
				nvidia,tristate = <TEGRA_PIN_ENABLE>;
				nvidia,enable-input = <TEGRA_PIN_DISABLE>;
			};

			cam1_strobe_pt1 { /* 31f4 */
				nvidia,pins = "cam1_strobe_pt1";
				nvidia,function = "rsvd1";
				nvidia,pull = <TEGRA_PIN_PULL_DOWN>;
				nvidia,tristate = <TEGRA_PIN_ENABLE>;
				nvidia,enable-input = <TEGRA_PIN_DISABLE>;
			};

			/* 5V Regulator - Battery */
			sata_led_active_pa5 { /* 304c */
				nvidia,pins = "sata_led_active_pa5";
				nvidia,function = "rsvd1";
				nvidia,pull = <TEGRA_PIN_PULL_NONE>;
				nvidia,tristate = <TEGRA_PIN_DISABLE>;
				nvidia,enable-input = <TEGRA_PIN_DISABLE>;
			};

			als_prox_int_px3 { /* 3228 */
				nvidia,pins = "als_prox_int_px3";
				nvidia,function = "rsvd0";
				nvidia,pull = <TEGRA_PIN_PULL_DOWN>;
				nvidia,tristate = <TEGRA_PIN_ENABLE>;
				nvidia,enable-input = <TEGRA_PIN_DISABLE>;
			};

			/* Temperature Sensor (TMP451) Alert */
			temp_alert_px4 { /* 322c */
				nvidia,pins = "temp_alert_px4";
				nvidia,function = "rsvd0";
				nvidia,pull = <TEGRA_PIN_PULL_UP>;
				nvidia,tristate = <TEGRA_PIN_ENABLE>;
				nvidia,enable-input = <TEGRA_PIN_ENABLE>;
			};

			/* Motion IRQ */
			motion_int_px2 { /* 3224 */
				nvidia,pins = "motion_int_px2";
				nvidia,function = "rsvd0";
				nvidia,pull = <TEGRA_PIN_PULL_DOWN>;
				nvidia,tristate = <TEGRA_PIN_ENABLE>;
				nvidia,enable-input = <TEGRA_PIN_ENABLE>;
			};

			/* Audio Codec (ALC5639) Headphone Detect */
			touch_rst_pv6 { /* 3214 */
				nvidia,pins = "touch_rst_pv6";
				nvidia,function = "rsvd0";
				nvidia,pull = <TEGRA_PIN_PULL_NONE>;
				nvidia,tristate = <TEGRA_PIN_ENABLE>;
				nvidia,enable-input = <TEGRA_PIN_ENABLE>;
			};

			touch_clk_pv7 { /* 3218 */
				nvidia,pins = "touch_clk_pv7";
				nvidia,function = "rsvd1";
				nvidia,pull = <TEGRA_PIN_PULL_DOWN>;
				nvidia,tristate = <TEGRA_PIN_ENABLE>;
				nvidia,enable-input = <TEGRA_PIN_DISABLE>;
			};

			/* Touchscreen (4CD60D) IRQ */
			touch_int_px1 { /* 3220 */
				nvidia,pins = "touch_int_px1";
				nvidia,function = "rsvd0";
				nvidia,pull = <TEGRA_PIN_PULL_UP>;
				nvidia,tristate = <TEGRA_PIN_ENABLE>;
				nvidia,enable-input = <TEGRA_PIN_ENABLE>;
			};

			modem_wake_ap_px0 { /* 321c */
				nvidia,pins = "modem_wake_ap_px0";
				nvidia,function = "rsvd0";
				nvidia,pull = <TEGRA_PIN_PULL_DOWN>;
				nvidia,tristate = <TEGRA_PIN_ENABLE>;
				nvidia,enable-input = <TEGRA_PIN_DISABLE>;
			};

			/* Power Button (Unused) */
			button_power_on_px5 { /* 3230 */
				nvidia,pins = "button_power_on_px5";
				nvidia,function = "rsvd0";
				nvidia,pull = <TEGRA_PIN_PULL_UP>;
				nvidia,tristate = <TEGRA_PIN_ENABLE>;
				nvidia,enable-input = <TEGRA_PIN_ENABLE>;
			};

			/* Volume Up Button */
			button_vol_up_px6 { /* 3234 */
				nvidia,pins = "button_vol_up_px6";
				nvidia,function = "rsvd0";
				nvidia,pull = <TEGRA_PIN_PULL_UP>;
				nvidia,tristate = <TEGRA_PIN_ENABLE>;
				nvidia,enable-input = <TEGRA_PIN_ENABLE>;
			};

			/* Volume Down Button */
			button_vol_down_px7 { /* 3238 */
				nvidia,pins = "button_vol_down_px7";
				nvidia,function = "rsvd0";
				nvidia,pull = <TEGRA_PIN_PULL_UP>;
				nvidia,tristate = <TEGRA_PIN_ENABLE>;
				nvidia,enable-input = <TEGRA_PIN_ENABLE>;
			};

			/* Home Button (RCM) */
			button_home_py1 { /* 3240 */
				nvidia,pins = "button_home_py1";
				nvidia,function = "rsvd0";
				nvidia,pull = <TEGRA_PIN_PULL_NONE>;
				nvidia,tristate = <TEGRA_PIN_ENABLE>;
				nvidia,enable-input = <TEGRA_PIN_ENABLE>;
			};

			/* LCD Backlight Power Enable */
			lcd_bl_en_pv1 { /* 3200 */
				nvidia,pins = "lcd_bl_en_pv1";
				nvidia,function = "rsvd0";
				nvidia,pull = <TEGRA_PIN_PULL_DOWN>;
				nvidia,tristate = <TEGRA_PIN_DISABLE>;
				nvidia,enable-input = <TEGRA_PIN_DISABLE>;
			};

			/* LCD Reset */
			lcd_rst_pv2 { /* 3204 */
				nvidia,pins = "lcd_rst_pv2";
				nvidia,function = "rsvd0";
				nvidia,pull = <TEGRA_PIN_PULL_DOWN>;
				nvidia,tristate = <TEGRA_PIN_DISABLE>;
				nvidia,enable-input = <TEGRA_PIN_DISABLE>;
			};

			/* USB-PD (BM92T36) Reset */
			ap_ready_pv5 { /* 3210 */
				nvidia,pins = "ap_ready_pv5";
				nvidia,function = "rsvd0";
				nvidia,pull = <TEGRA_PIN_PULL_DOWN>;
				nvidia,tristate = <TEGRA_PIN_DISABLE>;
				nvidia,enable-input = <TEGRA_PIN_DISABLE>;
			};

			/* Charger IC (BQ24193) IRQ */
			pz0 { /* 327c */
				nvidia,pins = "pz0";
				nvidia,function = "rsvd1";
				nvidia,pull = <TEGRA_PIN_PULL_UP>;
				nvidia,tristate = <TEGRA_PIN_ENABLE>;
				nvidia,enable-input = <TEGRA_PIN_ENABLE>;
			};

			/* SD Card Write Protect */
			pz3 { /* 3288 */
				nvidia,pins = "pz3";
				nvidia,function = "rsvd1";
				nvidia,pull = <TEGRA_PIN_PULL_UP>;
				nvidia,tristate = <TEGRA_PIN_ENABLE>;
				nvidia,enable-input = <TEGRA_PIN_ENABLE>;
			};

			/* USB-PD (BM92T36) IRQ */
			pk4 { /* 3264 */
				nvidia,pins = "pk4";
				nvidia,function = "rsvd1";
				nvidia,pull = <TEGRA_PIN_PULL_UP>;
				nvidia,tristate = <TEGRA_PIN_ENABLE>;
				nvidia,enable-input = <TEGRA_PIN_ENABLE>;
			};

			/* USB-PD (BM92T36) VCONN Power Enable */
			pk5 { /* 3268 */
				nvidia,pins = "pk5";
				nvidia,function = "rsvd1";
				nvidia,pull = <TEGRA_PIN_PULL_DOWN>;
				nvidia,tristate = <TEGRA_PIN_DISABLE>;
				nvidia,enable-input = <TEGRA_PIN_DISABLE>;
			};

			/* PMIC CPU (MAX77621_CPU) IRQ */
			pk6 { /* 326c */
				nvidia,pins = "pk6";
				nvidia,function = "rsvd1";
				nvidia,pull = <TEGRA_PIN_PULL_UP>;
				nvidia,tristate = <TEGRA_PIN_ENABLE>;
				nvidia,enable-input = <TEGRA_PIN_ENABLE>;
			};

			/* PMIC GPU (MAX77621_GPU) IRQ */
			pk7 { /* 3270 */
				nvidia,pins = "pk7";
				nvidia,function = "rsvd1";
				nvidia,pull = <TEGRA_PIN_PULL_UP>;
				nvidia,tristate = <TEGRA_PIN_ENABLE>;
				nvidia,enable-input = <TEGRA_PIN_ENABLE>;
			};

			pl0 { /* 3274 */
				nvidia,pins = "pl0";
				nvidia,function = "rsvd0";
				nvidia,pull = <TEGRA_PIN_PULL_DOWN>;
				nvidia,tristate = <TEGRA_PIN_DISABLE>;
				nvidia,enable-input = <TEGRA_PIN_DISABLE>;
			};

			/* Wi-Fi RF Disable */
			wifi_en_ph0 { /* 31b4 */
				nvidia,pins = "wifi_en_ph0";
				nvidia,function = "rsvd0";
				nvidia,pull = <TEGRA_PIN_PULL_DOWN>;
				nvidia,tristate = <TEGRA_PIN_DISABLE>;
				nvidia,enable-input = <TEGRA_PIN_DISABLE>;
			};

			/* Wi-Fi Reset */
			wifi_rst_ph1 { /* 31b8 */
				nvidia,pins = "wifi_rst_ph1";
				nvidia,function = "rsvd0";
				nvidia,pull = <TEGRA_PIN_PULL_DOWN>;
				nvidia,tristate = <TEGRA_PIN_DISABLE>;
				nvidia,enable-input = <TEGRA_PIN_DISABLE>;
			};

			/* Wi-Fi Wake Host */
			wifi_wake_ap_ph2 { /* 31bc */
				nvidia,pins = "wifi_wake_ap_ph2";
				nvidia,function = "rsvd0";
				nvidia,pull = <TEGRA_PIN_PULL_DOWN>;
				nvidia,tristate = <TEGRA_PIN_ENABLE>;
				nvidia,enable-input = <TEGRA_PIN_ENABLE>;
			};

			/* Bluetooth - AP -> Wake BT Module */
			ap_wake_bt_ph3 { /* 31c0 */
				nvidia,pins = "ap_wake_bt_ph3";
				nvidia,function = "rsvd0";
				nvidia,pull = <TEGRA_PIN_PULL_DOWN>;
				nvidia,tristate = <TEGRA_PIN_DISABLE>;
				nvidia,enable-input = <TEGRA_PIN_DISABLE>;
			};

			/* Bluetooth Reset */
			bt_rst_ph4 { /* 31c4 */
				nvidia,pins = "bt_rst_ph4";
				nvidia,function = "rsvd0";
				nvidia,pull = <TEGRA_PIN_PULL_DOWN>;
				nvidia,tristate = <TEGRA_PIN_DISABLE>;
				nvidia,enable-input = <TEGRA_PIN_DISABLE>;
			};

			/* Bluetooth - BT Module -> Wake AP */
			bt_wake_ap_ph5 { /* 31c8 */
				nvidia,pins = "bt_wake_ap_ph5";
				nvidia,function = "rsvd0";
				nvidia,pull = <TEGRA_PIN_PULL_NONE>;
				nvidia,tristate = <TEGRA_PIN_ENABLE>;
				nvidia,enable-input = <TEGRA_PIN_ENABLE>;
			};

			/* Joycon (R) Wake Detect */
			ph6 { /* 3250 */
				nvidia,pins = "ph6";
				nvidia,function = "rsvd0";
				nvidia,pull = <TEGRA_PIN_PULL_NONE>;
				nvidia,tristate = <TEGRA_PIN_ENABLE>;
				nvidia,enable-input = <TEGRA_PIN_ENABLE>;
			};

			/* Bluetooth GPIO5 */
			ap_wake_nfc_ph7 { /* 31cc */
				nvidia,pins = "ap_wake_nfc_ph7";
				nvidia,function = "rsvd0";
				nvidia,pull = <TEGRA_PIN_PULL_NONE>;
				nvidia,tristate = <TEGRA_PIN_DISABLE>;
				nvidia,enable-input = <TEGRA_PIN_DISABLE>;
			};

			/* LCD Power Enable +5V */
			nfc_en_pi0 { /* 31d0 */
				nvidia,pins = "nfc_en_pi0";
				nvidia,function = "rsvd0";
				nvidia,pull = <TEGRA_PIN_PULL_DOWN>;
				nvidia,tristate = <TEGRA_PIN_DISABLE>;
				nvidia,enable-input = <TEGRA_PIN_DISABLE>;
			};

			/* LCD Power Enable -5V */
			nfc_int_pi1 {
				nvidia,pins = "nfc_int_pi1";
				nvidia,function = "rsvd0";
				nvidia,pull = <TEGRA_PIN_PULL_DOWN>;
				nvidia,tristate = <TEGRA_PIN_DISABLE>;
				nvidia,enable-input = <TEGRA_PIN_DISABLE>;
			};

			gps_en_pi2 { /* 31d8 */
				nvidia,pins = "gps_en_pi2";
				nvidia,function = "rsvd0";
				nvidia,pull = <TEGRA_PIN_PULL_DOWN>;
				nvidia,tristate = <TEGRA_PIN_ENABLE>;
				nvidia,enable-input = <TEGRA_PIN_DISABLE>;
			};

			pcc7 { /* 3194 */
				nvidia,pins = "pcc7";
				nvidia,function = "rsvd0";
				nvidia,pull = <TEGRA_PIN_PULL_DOWN>;
				nvidia,tristate = <TEGRA_PIN_ENABLE>;
				nvidia,enable-input = <TEGRA_PIN_DISABLE>;
				nvidia,io-high-voltage = <TEGRA_PIN_ENABLE>;
			};

			dp_hpd0_pcc6 { /* 31b0 */
				nvidia,pins = "dp_hpd0_pcc6";
				nvidia,function = "rsvd1";
				nvidia,pull = <TEGRA_PIN_PULL_DOWN>;
				nvidia,tristate = <TEGRA_PIN_ENABLE>;
				nvidia,enable-input = <TEGRA_PIN_DISABLE>;
			};

			hdmi_int_dp_hpd_pcc1 { /* 319c */
				nvidia,pins = "hdmi_int_dp_hpd_pcc1";
				nvidia,function = "dp";
				nvidia,pull = <TEGRA_PIN_PULL_NONE>;
				nvidia,tristate = <TEGRA_PIN_ENABLE>;
				nvidia,enable-input = <TEGRA_PIN_ENABLE>;
				nvidia,io-high-voltage = <TEGRA_PIN_DISABLE>;
			};

			/* Fuel Gauge IC (MAX17050) IRQ */
			button_slide_sw_py0 { /* 323c */
				nvidia,pins = "button_slide_sw_py0";
				nvidia,function = "rsvd0";
				nvidia,pull = <TEGRA_PIN_PULL_UP>;
				nvidia,tristate = <TEGRA_PIN_ENABLE>;
				nvidia,enable-input = <TEGRA_PIN_ENABLE>;
			};

			pe7 { /* 324c */
				nvidia,pins = "pe7";
				nvidia,function = "rsvd0";
				nvidia,pull = <TEGRA_PIN_PULL_DOWN>;
				nvidia,tristate = <TEGRA_PIN_ENABLE>;
				nvidia,enable-input = <TEGRA_PIN_DISABLE>;
			};

			lcd_gpio1_pv3 { /* 3208 */
				nvidia,pins = "lcd_gpio1_pv3";
				nvidia,function = "rsvd1";
				nvidia,pull = <TEGRA_PIN_PULL_DOWN>;
				nvidia,tristate = <TEGRA_PIN_ENABLE>;
				nvidia,enable-input = <TEGRA_PIN_DISABLE>;
			};
		};

		pinmux_unused_lowpower: unused_lowpower {
			spi2_mosi_pb4 { /* 3064 */
				nvidia,pins = "spi2_mosi_pb4";
				nvidia,function = "rsvd2";
				nvidia,pull = <TEGRA_PIN_PULL_DOWN>;
				nvidia,tristate = <TEGRA_PIN_ENABLE>;
				nvidia,enable-input = <TEGRA_PIN_DISABLE>;
			};

			spi2_miso_pb5 { /* 3068 */
				nvidia,pins = "spi2_miso_pb5";
				nvidia,function = "rsvd2";
				nvidia,pull = <TEGRA_PIN_PULL_DOWN>;
				nvidia,tristate = <TEGRA_PIN_ENABLE>;
				nvidia,enable-input = <TEGRA_PIN_DISABLE>;
			};

			spi2_sck_pb6 { /* 306c */
				nvidia,pins = "spi2_sck_pb6";
				nvidia,function = "rsvd2";
				nvidia,pull = <TEGRA_PIN_PULL_DOWN>;
				nvidia,tristate = <TEGRA_PIN_ENABLE>;
				nvidia,enable-input = <TEGRA_PIN_DISABLE>;
			};

			spi2_cs0_pb7 { /* 3070 */
				nvidia,pins = "spi2_cs0_pb7";
				nvidia,function = "rsvd2";
				nvidia,pull = <TEGRA_PIN_PULL_DOWN>;
				nvidia,tristate = <TEGRA_PIN_ENABLE>;
				nvidia,enable-input = <TEGRA_PIN_DISABLE>;
			};

			spi2_cs1_pdd0 { /* 3074 */
				nvidia,pins = "spi2_cs1_pdd0";
				nvidia,function = "rsvd1";
				nvidia,pull = <TEGRA_PIN_PULL_DOWN>;
				nvidia,tristate = <TEGRA_PIN_ENABLE>;
				nvidia,enable-input = <TEGRA_PIN_DISABLE>;
			};

			pa6 { /* 3244 */
				nvidia,pins = "pa6";
				nvidia,function = "rsvd1";
				nvidia,pull = <TEGRA_PIN_PULL_DOWN>;
				nvidia,tristate = <TEGRA_PIN_ENABLE>;
				nvidia,enable-input = <TEGRA_PIN_DISABLE>;
			};

			pz2 { /* 3284 */
				nvidia,pins = "pz2";
				nvidia,function = "rsvd3";
				nvidia,pull = <TEGRA_PIN_PULL_DOWN>;
				nvidia,tristate = <TEGRA_PIN_ENABLE>;
				nvidia,enable-input = <TEGRA_PIN_ENABLE>;
			};

			gps_rst_pi3 { /* 31dc */
				nvidia,pins = "gps_rst_pi3";
				nvidia,function = "rsvd0";
				nvidia,pull = <TEGRA_PIN_PULL_DOWN>;
				nvidia,tristate = <TEGRA_PIN_ENABLE>;
				nvidia,enable-input = <TEGRA_PIN_DISABLE>;
			};

			qspi_io0_pee2 { /* 3090 */
				nvidia,pins = "qspi_io0_pee2";
				nvidia,function = "qspi";
				nvidia,pull = <TEGRA_PIN_PULL_UP>;
				nvidia,tristate = <TEGRA_PIN_DISABLE>;
				nvidia,enable-input = <TEGRA_PIN_DISABLE>;
				nvidia,schmitt = <TEGRA_PIN_ENABLE>;
			};

			qspi_io1_pee3 { /* 3094 */
				nvidia,pins = "qspi_io1_pee3";
				nvidia,function = "qspi";
				nvidia,pull = <TEGRA_PIN_PULL_DOWN>;
				nvidia,tristate = <TEGRA_PIN_ENABLE>;
				nvidia,enable-input = <TEGRA_PIN_ENABLE>;
				nvidia,schmitt = <TEGRA_PIN_ENABLE>;
			};

			qspi_sck_pee0 { /* 3088 */
				nvidia,pins = "qspi_sck_pee0";
				nvidia,function = "qspi";
				nvidia,pull = <TEGRA_PIN_PULL_UP>;
				nvidia,tristate = <TEGRA_PIN_DISABLE>;
				nvidia,enable-input = <TEGRA_PIN_DISABLE>;
				nvidia,schmitt = <TEGRA_PIN_ENABLE>;
			};

			qspi_cs_n_pee1 { /* 308c */
				nvidia,pins = "qspi_cs_n_pee1";
				nvidia,function = "qspi";
				nvidia,pull = <TEGRA_PIN_PULL_UP>;
				nvidia,tristate = <TEGRA_PIN_DISABLE>;
				nvidia,enable-input = <TEGRA_PIN_DISABLE>;
				nvidia,schmitt = <TEGRA_PIN_ENABLE>;
			};

			qspi_io2_pee4 { /* 3098 */
				nvidia,pins = "qspi_io2_pee4";
				nvidia,function = "rsvd1";
				nvidia,pull = <TEGRA_PIN_PULL_DOWN>;
				nvidia,tristate = <TEGRA_PIN_ENABLE>;
				nvidia,enable-input = <TEGRA_PIN_DISABLE>;
				nvidia,schmitt = <TEGRA_PIN_ENABLE>;
			};

			qspi_io3_pee5 { /* 309c */
				nvidia,pins = "qspi_io3_pee5";
				nvidia,function = "rsvd1";
				nvidia,pull = <TEGRA_PIN_PULL_DOWN>;
				nvidia,tristate = <TEGRA_PIN_ENABLE>;
				nvidia,enable-input = <TEGRA_PIN_DISABLE>;
				nvidia,schmitt = <TEGRA_PIN_ENABLE>;
			};

			spdif_out_pcc2 { /* 31a0 */
				nvidia,pins = "spdif_out_pcc2";
				nvidia,function = "rsvd1";
				nvidia,pull = <TEGRA_PIN_PULL_UP>;
				nvidia,tristate = <TEGRA_PIN_ENABLE>;
				nvidia,enable-input = <TEGRA_PIN_ENABLE>;
			};
		};

		drive_default: drive {
			aud_mclk_pbb0 {
				nvidia,pins = "aud_mclk_pbb0";
				nvidia,pull-down-strength = <0x10>;
				nvidia,pull-up-strength = <0x10>;
			};
			cam1_mclk_ps0 {
				nvidia,pins = "cam1_mclk_ps0";
				nvidia,pull-down-strength = <0x10>;
				nvidia,pull-up-strength = <0x10>;
			};
			cam2_mclk_ps1 {
				nvidia,pins = "cam2_mclk_ps1";
				nvidia,pull-down-strength = <0x10>;
				nvidia,pull-up-strength = <0x10>;
			};
			cam_af_en_ps5 {
				nvidia,pins = "cam_af_en_ps5";
				nvidia,pull-down-strength = <0x10>;
				nvidia,pull-up-strength = <0x10>;
			};
			cam_flash_en_ps6 {
				nvidia,pins = "cam_flash_en_ps6";
				nvidia,pull-down-strength = <0x10>;
				nvidia,pull-up-strength = <0x10>;
			};
			cam_i2c_scl_ps2 {
				nvidia,pins = "cam_i2c_scl_ps2";
				nvidia,pull-down-strength = <0x1F>;
				nvidia,pull-up-strength = <0x00>;
			};
			cam_i2c_sda_ps3 {
				nvidia,pins = "cam_i2c_sda_ps3";
				nvidia,pull-down-strength = <0x1F>;
				nvidia,pull-up-strength = <0x00>;
			};
			dmic3_clk_pe4 {
				nvidia,pins = "dmic3_clk_pe4";
				nvidia,pull-down-strength = <0x1F>;
				nvidia,pull-up-strength = <0x1F>;
			};
			dmic3_dat_pe5 {
				nvidia,pins = "dmic3_dat_pe5";
				nvidia,pull-down-strength = <0x1F>;
				nvidia,pull-up-strength = <0x1F>;
			};
			dap4_din_pj5 {
				nvidia,pins = "dap4_din_pj5";
				nvidia,pull-down-strength = <0x10>;
				nvidia,pull-up-strength = <0x10>;
			};
			dap4_dout_pj6 {
				nvidia,pins = "dap4_dout_pj6";
				nvidia,pull-down-strength = <0x10>;
				nvidia,pull-up-strength = <0x10>;
			};
			dap4_fs_pj4 {
				nvidia,pins = "dap4_fs_pj4";
				nvidia,pull-down-strength = <0x10>;
				nvidia,pull-up-strength = <0x10>;
			};
			dap4_sclk_pj7 {
				nvidia,pins = "dap4_sclk_pj7";
				nvidia,pull-down-strength = <0x10>;
				nvidia,pull-up-strength = <0x10>;
			};
			dmic1_clk_pe0 {
				nvidia,pins = "dmic1_clk_pe0";
				nvidia,pull-down-strength = <0x10>;
				nvidia,pull-up-strength = <0x10>;
			};
			dmic1_dat_pe1 {
				nvidia,pins = "dmic1_dat_pe1";
				nvidia,pull-down-strength = <0x10>;
				nvidia,pull-up-strength = <0x10>;
			};
			dmic2_clk_pe2 {
				nvidia,pins = "dmic2_clk_pe2";
				nvidia,pull-down-strength = <0x10>;
				nvidia,pull-up-strength = <0x10>;
			};
			dmic2_dat_pe3 {
				nvidia,pins = "dmic2_dat_pe3";
				nvidia,pull-down-strength = <0x10>;
				nvidia,pull-up-strength = <0x10>;
			};
			touch_clk_pv7 {
				nvidia,pins = "touch_clk_pv7";
				nvidia,pull-down-strength = <0x14>;
				nvidia,pull-up-strength = <0x14>;
			};
			gen1_i2c_scl_pj1 {
				nvidia,pins = "gen1_i2c_scl_pj1";
				nvidia,pull-down-strength = <0x1F>;
				nvidia,pull-up-strength = <0x00>;
			};
			gen1_i2c_sda_pj0 {
				nvidia,pins = "gen1_i2c_sda_pj0";
				nvidia,pull-down-strength = <0x1F>;
				nvidia,pull-up-strength = <0x00>;
			};
			gen2_i2c_scl_pj2 {
				nvidia,pins = "gen2_i2c_scl_pj2";
				nvidia,pull-down-strength = <0x1F>;
				nvidia,pull-up-strength = <0x00>;
			};
			gen2_i2c_sda_pj3 {
				nvidia,pins = "gen2_i2c_sda_pj3";
				nvidia,pull-down-strength = <0x1F>;
				nvidia,pull-up-strength = <0x00>;
			};
			gen3_i2c_scl_pf0 {
				nvidia,pins = "gen3_i2c_scl_pf0";
				nvidia,pull-down-strength = <0x7>;
				nvidia,pull-up-strength = <0x00>;
			};
			gen3_i2c_sda_pf1 {
				nvidia,pins = "gen3_i2c_sda_pf1";
				nvidia,pull-down-strength = <0x7>;
				nvidia,pull-up-strength = <0x00>;
			};
			pwr_i2c_scl_py3 {
				nvidia,pins = "pwr_i2c_scl_py3";
				nvidia,pull-down-strength = <0x1F>;
				nvidia,pull-up-strength = <0x00>;
			};
			pwr_i2c_sda_py4 {
				nvidia,pins = "pwr_i2c_sda_py4";
				nvidia,pull-down-strength = <0x1F>;
				nvidia,pull-up-strength = <0x00>;
			};
			spi1_cs0_pc3 {
				nvidia,pins = "spi1_cs0_pc3";
				nvidia,pull-down-strength = <0x00>;
				nvidia,pull-up-strength = <0x00>;
			};
			spi1_cs1_pc4 {
				nvidia,pins = "spi1_cs1_pc4";
				nvidia,pull-down-strength = <0x00>;
				nvidia,pull-up-strength = <0x00>;
			};
			spi1_miso_pc1 {
				nvidia,pins = "spi1_miso_pc1";
				nvidia,pull-down-strength = <0x00>;
				nvidia,pull-up-strength = <0x00>;
			};
			spi1_mosi_pc0 {
				nvidia,pins = "spi1_mosi_pc0";
				nvidia,pull-down-strength = <0x00>;
				nvidia,pull-up-strength = <0x00>;
			};
			spi1_sck_pc2 {
				nvidia,pins = "spi1_sck_pc2";
				nvidia,pull-down-strength = <0x00>;
				nvidia,pull-up-strength = <0x00>;
			};
			spi2_cs0_pb7 {
				nvidia,pins = "spi2_cs0_pb7";
				nvidia,pull-down-strength = <0x00>;
				nvidia,pull-up-strength = <0x00>;
			};
			spi2_cs1_pdd0 {
				nvidia,pins = "spi2_cs1_pdd0";
				nvidia,pull-down-strength = <0x00>;
				nvidia,pull-up-strength = <0x00>;
			};
			spi2_miso_pb5 {
				nvidia,pins = "spi2_miso_pb5";
				nvidia,pull-down-strength = <0x00>;
				nvidia,pull-up-strength = <0x00>;
			};
			spi2_mosi_pb4 {
				nvidia,pins = "spi2_mosi_pb4";
				nvidia,pull-down-strength = <0x00>;
				nvidia,pull-up-strength = <0x00>;
			};
			spi2_sck_pb6 {
				nvidia,pins = "spi2_sck_pb6";
				nvidia,pull-down-strength = <0x00>;
				nvidia,pull-up-strength = <0x00>;
			};
			dvfs_clk_pbb2 {
				nvidia,pins = "dvfs_clk_pbb2";
				nvidia,pull-down-strength = <0x1F>;
				nvidia,pull-up-strength = <0x1F>;
			};
			dvfs_pwm_pbb1 {
				nvidia,pins = "dvfs_pwm_pbb1";
				nvidia,pull-down-strength = <0x04>;
				nvidia,pull-up-strength = <0x14>;
			};
			pz0 {
				nvidia,pins = "pz0";
				nvidia,pull-down-strength = <0x10>;
				nvidia,pull-up-strength = <0x10>;
			};
			pz1 {
				nvidia,pins = "pz1";
				nvidia,pull-down-strength = <0x10>;
				nvidia,pull-up-strength = <0x10>;
			};
			gpio_x1_aud_pbb3 {
				nvidia,pins = "gpio_x1_aud_pbb3";
				nvidia,pull-down-strength = <0x04>;
				nvidia,pull-up-strength = <0x14>;
			};
			gpio_x3_aud_pbb4 {
				nvidia,pins = "gpio_x3_aud_pbb4";
				nvidia,pull-down-strength = <0x04>;
				nvidia,pull-up-strength = <0x14>;
			};
			uart3_tx_pd1 {
				nvidia,pins = "uart3_tx_pd1";
				nvidia,pull-down-strength = <0x04>;
				nvidia,pull-up-strength = <0x14>;
			};
			uart3_rx_pd2 {
				nvidia,pins = "uart3_rx_pd2";
				nvidia,pull-down-strength = <0x04>;
				nvidia,pull-up-strength = <0x14>;
			};
			uart3_rts_pd3 {
				nvidia,pins = "uart3_rts_pd3";
				nvidia,pull-down-strength = <0x04>;
				nvidia,pull-up-strength = <0x14>;
			};
			uart3_cts_pd4 {
				nvidia,pins = "uart3_cts_pd4";
				nvidia,pull-down-strength = <0x04>;
				nvidia,pull-up-strength = <0x14>;
			};
		};
	};

	/* i2c5 @ 400000hz
	1b: cpu_max_reg
	1c: gpu_max_reg
	3c: max77620
	68: max77620_rtc
	*/
	i2c@7000d000 {
		status = "okay";
		clock-frequency = <400000>;

		cpu_max_reg: pmic@1b {
			compatible = "maxim,max77621";
			reg = <0x1b>;
			interrupt-parent = <&gpio>;
			interrupts = <TEGRA_GPIO(K, 6) IRQ_TYPE_LEVEL_LOW>;
			regulator-name = "vdd-cpu";
			regulator-min-microvolt = <618750>;
			regulator-max-microvolt = <1400000>;
			regulator-max-microamp = <9000000>;
			regulator-init-microvolt = <1000000>;
			regulator-ramp-delay = <12000>;
			regulator-enable-ramp-delay = <500>;
			regulator-disable-ramp-delay = <60000>;
			regulator-boot-on;
			regulator-always-on;
			#thermal-sensor-cells = <0>;
			maxim,enable-active-discharge;
			maxim,enable-falling-slew-rate;
			maxim,enable-remote-sense;
			maxim,externally-enable;
			maxim,sleep-on-dvs;
			maxim,dvs-default-state = <1>;
			maxim,enable-gpio = <&max77620 5 0>;
			junction-warn-millicelsius = <120000>;
		};

		gpu_max_reg: pmic@1c {
			compatible = "maxim,max77621";
			reg = <0x1c>;
			interrupt-parent = <&gpio>;
			interrupts = <TEGRA_GPIO(K, 7) IRQ_TYPE_LEVEL_LOW>;
			regulator-name = "vdd-gpu";
			regulator-min-microvolt = <618750>;
			regulator-max-microvolt = <1150000>;
			regulator-max-microamp = <15000000>;
			regulator-init-microvolt = <1000000>;
			regulator-ramp-delay = <12000>;
			regulator-enable-ramp-delay = <500>;
			regulator-disable-ramp-delay = <60000>;
			#thermal-sensor-cells = <0>;
			maxim,enable-active-discharge;
			maxim,enable-falling-slew-rate;
			maxim,enable-remote-sense;
			maxim,enable-bias-control;
			maxim,dvs-default-state = <1>;
			maxim,enable-gpio = <&max77620 6 0>;
			junction-warn-millicelsius = <120000>;
		};

		max77620: max77620@3c {
			compatible = "maxim,max77620";
			status = "okay";
			reg = <0x3c>;
			interrupts = <GIC_SPI 86 IRQ_TYPE_LEVEL_HIGH>; /* TEGRA_GPIO(K, 6) / PMU_EXT */

			#address-cells = <1>;

			#interrupt-cells = <2>;
			interrupt-controller;

			gpio-controller;
			#gpio-cells = <2>;

			#thermal-sensor-cells = <0>;

			pinctrl-names = "default";
			pinctrl-0 = <&max77620_default>;

			max77620_default: pinmux {
				gpio0 {
					pins = "gpio0";
					function = "gpio";
				};

				gpio1 {
					pins = "gpio1";
					function = "gpio";
				};

				gpio2 {
					pins = "gpio2";
					function = "fps-out";
					drive-open-drain = <1>;
					maxim,active-fps-source = <MAX77620_FPS_SRC_0>;
					maxim,active-fps-power-up-slot = <0>;
					maxim,active-fps-power-down-slot = <7>;
				};

				/* vdd_3v3 */
				gpio3 {
					pins = "gpio3";
					function = "fps-out";
					drive-open-drain = <1>;
					maxim,active-fps-source = <MAX77620_FPS_SRC_0>;
					maxim,active-fps-power-up-slot = <4>;
					maxim,active-fps-power-down-slot = <2>;
				};

				gpio4 {
					pins = "gpio4";
					function = "32k-out1";
				};

				/* 5: cpu_max_reg, 6: gpu_max_reg, 7: dsi panel */
				gpio5_6_7 {
					pins = "gpio5", "gpio6", "gpio7";
					function = "gpio";
					drive-push-pull = <1>;
				};
			};

			watchdog {
				maxim,wdt-boot-timeout = <16>;
				maxim,wdt-clear-time = <13>;
				status = "okay";
				dt-override-status-odm-data = <0x00020000 0x00020000>;
			};

			fps {
				fps0 {
					maxim,fps-event-source = <MAX77620_FPS_EVENT_SRC_EN0>;
					maxim,suspend-fps-time-period-us = <5120>;
				};

				fps1 {
					maxim,suspend-fps-time-period-us = <5120>;
					maxim,fps-event-source = <MAX77620_FPS_EVENT_SRC_EN1>;
				};

				fps2 {
					maxim,suspend-fps-time-period-us = <5120>;
					maxim,fps-event-source = <MAX77620_FPS_EVENT_SRC_EN0>;
				};
			};

			regulators {
				in-sd0-supply = <&battery_reg>;
				in-sd1-supply = <&battery_reg>;
				in-sd2-supply = <&battery_reg>;
				in-sd3-supply = <&battery_reg>;

				in-ldo0-1-supply = <&max77620_sd2>;
				in-ldo2-supply = <&vdd_3v3>;
				in-ldo3-5-supply = <&vdd_3v3>;
				in-ldo4-6-supply = <&battery_reg>;
				in-ldo7-8-supply = <&max77620_sd2>;

				max77620_sd0: sd0 {
					regulator-name = "vdd-core";
					regulator-min-microvolt = <625000>;
					regulator-max-microvolt = <1400000>;
					regulator-boot-on;
					regulator-always-on;
					maxim,active-fps-source = <MAX77620_FPS_SRC_1>;
					maxim,active-fps-power-up-slot = <1>;
					maxim,active-fps-power-down-slot = <7>;
					regulator-enable-ramp-delay = <50>;
					regulator-disable-ramp-delay = <4080>;
					maxim,ramp-rate-setting = <27500>;
					regulator-ramp-delay = <27500>;
				};

				max77620_sd1: sd1 {
					regulator-name = "vddio-ddr";
					regulator-min-microvolt = <1050000>;
					regulator-max-microvolt = <1200000>;
					regulator-always-on;
					regulator-boot-on;
					/* regulator-init-microvolt = <1125000>; */ /* Controlled by bootloader */
					maxim,active-fps-source = <MAX77620_FPS_SRC_0>;
					maxim,active-fps-power-up-slot = <5>;
					maxim,active-fps-power-down-slot = <1>;
					regulator-enable-ramp-delay = <1000>;
					regulator-disable-ramp-delay = <145800>;
					maxim,ramp-rate-setting = <27500>;
					regulator-ramp-delay = <27500>;
				};

				max77620_sd2: sd2 {
					regulator-name = "vdd-pre-reg";
					regulator-min-microvolt = <1325000>;
					regulator-max-microvolt = <1350000>;
					regulator-always-on;
					regulator-boot-on;
					maxim,active-fps-source = <MAX77620_FPS_SRC_1>;
					maxim,active-fps-power-up-slot = <2>;
					maxim,active-fps-power-down-slot = <5>;
					regulator-enable-ramp-delay = <50>;
					regulator-disable-ramp-delay = <32000>;
					maxim,ramp-rate-setting = <27500>;
					regulator-ramp-delay = <27500>;
				};

				max77620_sd3: sd3 {
					regulator-name = "vdd-1v8";
					regulator-min-microvolt = <1800000>;
					regulator-max-microvolt = <1800000>;
					regulator-always-on;
					regulator-boot-on;
					maxim,active-fps-source = <MAX77620_FPS_SRC_0>;
					maxim,active-fps-power-up-slot = <3>;
					maxim,active-fps-power-down-slot = <3>;
					regulator-enable-ramp-delay = <50>;
					regulator-disable-ramp-delay = <118000>;
					maxim,ramp-rate-setting = <27500>;
					regulator-ramp-delay = <27500>;
				};

				/* Display Panel */
				max77620_ldo0: ldo0 {
					regulator-name = "avdd-sys";
					regulator-min-microvolt = <1200000>;
					regulator-max-microvolt = <1200000>;
					regulator-boot-on; /* Must be set for seamless display */
					maxim,active-fps-source = <MAX77620_FPS_SRC_NONE>;
					maxim,active-fps-power-up-slot = <0>;
					maxim,active-fps-power-down-slot = <7>;
					regulator-enable-ramp-delay = <50>;
					regulator-disable-ramp-delay = <4000>;
					maxim,ramp-rate-setting = <50000>;
					regulator-ramp-delay = <50000>;
				};

				/* XUSB, PCIE */
				max77620_ldo1: ldo1 {
					regulator-name = "vdd-pex";
					regulator-min-microvolt = <1050000>;
					regulator-max-microvolt = <1050000>;
					maxim,active-fps-source = <MAX77620_FPS_SRC_NONE>;
					maxim,active-fps-power-up-slot = <0>;
					maxim,active-fps-power-down-slot = <7>;
					regulator-enable-ramp-delay = <50>;
					regulator-disable-ramp-delay = <6000>;
					maxim,ramp-rate-setting = <50000>;
					regulator-ramp-delay = <50000>;
				};

				/* SD Card (SDMMC1) */
				max77620_ldo2: ldo2 {
					regulator-name = "vddio-sdmmc1";
					regulator-min-microvolt = <1800000>;
					regulator-max-microvolt = <3300000>;
					maxim,active-fps-source = <MAX77620_FPS_SRC_NONE>;
					maxim,active-fps-power-up-slot = <0>;
					maxim,active-fps-power-down-slot = <7>;
					regulator-enable-ramp-delay = <100>;
					regulator-disable-ramp-delay = <7000>;
					maxim,ramp-rate-setting = <50000>;
					regulator-ramp-delay = <50000>;
				};

				/* GC Card Vdd */
				max77620_ldo3: ldo3 {
					regulator-name = "vdd-gc-3v1";
					regulator-min-microvolt = <3100000>;
					regulator-max-microvolt = <3100000>;
					maxim,active-fps-source = <MAX77620_FPS_SRC_NONE>;
					maxim,active-fps-power-up-slot = <0>;
					maxim,active-fps-power-down-slot = <7>;
					regulator-enable-ramp-delay = <100>;
					regulator-disable-ramp-delay = <3000>;
					maxim,ramp-rate-setting = <50000>;
					regulator-ramp-delay = <50000>;
				};

				/* RTC domain. Always On */
				max77620_ldo4: ldo4 {
					regulator-name = "vdd-rtc";
					regulator-min-microvolt = <850000>;
					regulator-max-microvolt = <850000>;
					regulator-always-on;
					regulator-boot-on;
					maxim,active-fps-power-up-slot = <1>;
					maxim,active-fps-power-down-slot = <7>;
					maxim,active-fps-source = <MAX77620_FPS_SRC_0>;
					regulator-enable-ramp-delay = <50>;
					regulator-disable-ramp-delay = <610>;
					maxim,ramp-rate-setting = <50000>;
					regulator-ramp-delay = <50000>;
				};

				/* GC Card Vddio */
				max77620_ldo5: ldo5 {
					regulator-name = "vdd-gc-1v8";
					regulator-min-microvolt = <1800000>;
					regulator-max-microvolt = <1800000>;
					maxim,active-fps-source = <MAX77620_FPS_SRC_NONE>;
					maxim,active-fps-power-up-slot = <0>;
					maxim,active-fps-power-down-slot = <7>;
					regulator-enable-ramp-delay = <60>;
					regulator-disable-ramp-delay = <3000>;
					maxim,ramp-rate-setting = <50000>;
					regulator-ramp-delay = <50000>;
				};

				/* Touch Panel, ALS */
				max77620_ldo6: ldo6 {
					regulator-name = "vdd-tp-2v9";
					regulator-min-microvolt = <2900000>;
					regulator-max-microvolt = <2900000>;
					regulator-boot-on; /* Decrease por time for Touch Panel. */
					maxim,active-fps-source = <MAX77620_FPS_SRC_NONE>;
					maxim,active-fps-power-up-slot = <0>;
					maxim,active-fps-power-down-slot = <7>;
					regulator-enable-ramp-delay = <100>;
					regulator-disable-ramp-delay = <3000>;
					maxim,ramp-rate-setting = <50000>;
					regulator-ramp-delay = <50000>;
				};

				max77620_ldo7: ldo7 {
					regulator-name = "vdd-gen-pll-edp";
					regulator-min-microvolt = <1050000>;
					regulator-max-microvolt = <1050000>;
					maxim,active-fps-source = <MAX77620_FPS_SRC_1>;
					maxim,active-fps-power-up-slot = <3>;
					maxim,active-fps-power-down-slot = <4>;
					regulator-enable-ramp-delay = <50>;
					regulator-disable-ramp-delay = <2768>;
					maxim,ramp-rate-setting = <50000>;
					regulator-ramp-delay = <50000>;
				};

				/* DP */
				max77620_ldo8: ldo8 {
					regulator-name = "vdd-hdmi-dp";
					regulator-min-microvolt = <1050000>;
					regulator-max-microvolt = <1050000>;
					maxim,active-fps-source = <MAX77620_FPS_SRC_NONE>;
					maxim,active-fps-power-up-slot = <0>;
					maxim,active-fps-power-down-slot = <7>;
					regulator-enable-ramp-delay = <100>;
					regulator-disable-ramp-delay = <4000>;
					maxim,ramp-rate-setting = <50000>;
					regulator-ramp-delay = <50000>;
				};

				onoff {
					maxim,onoff-keycode = <KEY_POWER>;
				};
			};
		};
	};

	pmc@7000e400 {
		status = "okay";
		#address-cells = <1>;

		nvidia,invert-interrupt;
		nvidia,suspend-mode = <0>;
		nvidia,cpu-pwr-good-time = <0>;
		nvidia,cpu-pwr-off-time = <0>;
		nvidia,core-pwr-good-time = <13092 7752>;
		nvidia,core-pwr-off-time = <44188>;
		nvidia,core-pwr-req-active-high;
		nvidia,sys-clock-req-active-high;

		iopad-defaults {
			audio-hv-pads {
				pins = "audio-hv";
				power-source = <TEGRA_IO_PAD_VOLTAGE_1V8>;
			};

			spi-hv-pads {
				pins = "spi-hv";
				power-source = <TEGRA_IO_PAD_VOLTAGE_1V8>;
			};

			gpio-pads {
				pins = "gpio";
				power-source = <TEGRA_IO_PAD_VOLTAGE_1V8>;
			};

			sdmmc1-pads {
				pins = "sdmmc1";
			};

			sdmmc3-pads {
				pins = "sdmmc3";
				power-source = <TEGRA_IO_PAD_VOLTAGE_1V8>;
				low-power-enable;
			};
		};
	};

	xusb: usb@70090000 {
		status = "okay";

		phys = <&{/padctl@7009f000/pads/usb2/lanes/usb2-0}>,
			<&{/padctl@7009f000/pads/pcie/lanes/pcie-6}>;
		phy-names = "usb2-0", "usb3-0";

		extcon = <&bm92t 0>;
		extcon-cable-names = "vbus";

		avdd-usb-supply = <&vdd_3v3>;
		dvddio-pex-supply = <&max77620_ldo1>;
		hvddio-pex-supply = <&max77620_sd3>;
		avdd-pll-utmip-supply = <&max77620_sd3>;
		avdd-pll-uerefe-supply = <&max77620_ldo7>;
		dvdd-pex-pll-supply = <&max77620_ldo1>;
		hvdd-pex-pll-e-supply = <&max77620_sd3>;
		dvdd-usb-ss-pll-supply = <&max77620_ldo7>;
		hvdd-usb-ss-pll-e-supply = <&max77620_sd3>;
	};

	padctl@7009f000 {
		status =  "okay";

		avdd-pll-utmip-supply = <&max77620_sd3>;
		avdd-pll-uerefe-supply = <&max77620_ldo7>;
		dvdd-pex-pll-supply = <&max77620_ldo1>;
		hvdd-pex-pll-e-supply = <&max77620_sd3>;

		pads {
			usb2 {
				status = "okay";

				lanes {
					usb2-0 {
						nvidia,function = "xusb";
						status = "okay";
					};
				};
			};

			pcie {
				status = "okay";

				lanes {
					/* bcm4356A3-wifi */
					pcie-0 {
						nvidia,function = "pcie-x1";
						status = "okay";
					};
					/* Unused ports */
					pcie-1 {
						nvidia,function = "pcie-x4";
						status = "okay";
					};
					pcie-2 {
						nvidia,function = "pcie-x4";
						status = "okay";
					};
					pcie-3 {
						nvidia,function = "pcie-x4";
						status = "okay";
					};
					pcie-4 {
						nvidia,function = "pcie-x4";
						status = "okay";
					};
					/* XUSB */
					pcie-5 {
						nvidia,function = "usb3-ss";
						status = "okay";
					};
					pcie-6 {
						nvidia,function = "usb3-ss";
						status = "okay";
					};
				};
			};
		};

		ports {
			usb2-0 {
				status = "okay";
				mode = "otg";

				usb-role-switch;
				vbus-supply = <&battery_reg>;

				#address-cells = <1>;
				#size-cells = <0>;

				usb_port_0: endpoint@0 {
					reg = <0>;
					remote-endpoint = <&usb_con_ep>;
				};
			};

			usb3-0 {
				status = "okay";
				nvidia,usb2-companion = <0>;
			};
		};
	};

	xudc: usb@700d0000 {
		status = "okay";

		phys = <&{/padctl@7009f000/pads/usb2/lanes/usb2-0}>,
			<&{/padctl@7009f000/pads/pcie/lanes/pcie-6}>;
		phy-names = "usb2-0", "usb3-0";

		extcon = <&bm92t 1>;
		extcon-cable-names = "id";

		avddio-usb-supply = <&max77620_ldo1>;
		hvdd-usb-supply = <&vdd_3v3>;
	};

	aconnect@702c0000 {
		status = "okay";

		dma-controller@702e2000 {
			status = "okay";
		};

		interrupt-controller@702f9000 {
			status = "okay";
		};
	};

	i2c@7000c400 {
		bh1730fvc@29 {
			status = "okay";
		};
	};
};
